# A33G53x register map
Vendor: ABOV Semiconductor Co., Ltd.; File version: 0.1
CPU: CM3 r1p0, little endian, no MPU, no FPU, 3 interrupt priority bits
Registers are 32-bit, read-write, reset 0x0 unless marked. A register's access mark holds for its fields unless they carry their own. Offsets are from the block's base; [hi:lo] are bit positions; {n}, {i} and the like mark numbered series.

## FMC — INTERNAL FLASH MEMORY
Base 0x40000100
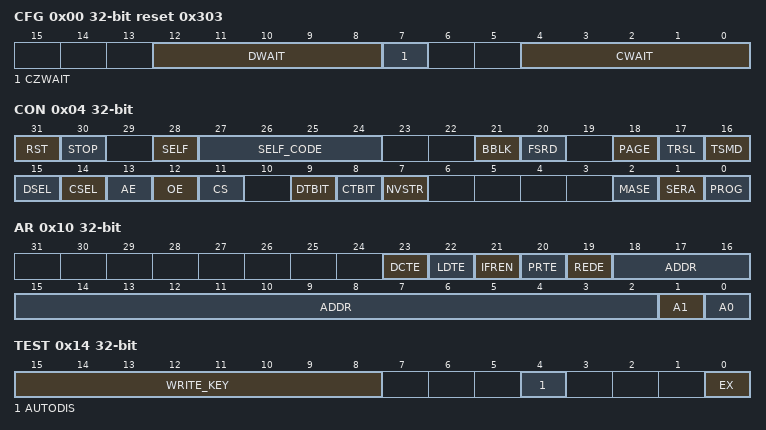
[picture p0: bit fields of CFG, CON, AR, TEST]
0x00 CFG reset 0x303 — Flash Memory Configuration Register
  [12:8] DWAIT — Wait value of data flash memory
  [7] CZWAIT — Zero wait value of code flash memory
  [4:0] CWAIT — Wait value of code flash memory
0x04 CON — Flash Memory Control Register
  [31] RST — Flash Reset Signal Control
  [30] STOP — Flash Status Control
  [28] SELF — Flash Self Program Control
  [27:24] SELF_CODE — Flash self program mode, can be written in conjunction with the PMCON[27:24] = 0110
  [21] BBLK — Boot Block Protection
  [20] FSRD — Fuse area activation(for flash internal test)
  [18] PAGE — Erase flash on a page(512 bytes) unit. Not supported in self-program mode
  [17] TRSL — Allow access to registers for flash testing(For flash internal test)
  [16] TSMD — Enter Test Mode(for flash internal test)
  [15] DSEL — Data Flash Select
  [14] CSEL — Code Flash Select
  [13] AE — Address Latch Enable
  [12] OE — Output Enable(Code flash program mode)
  [11] CS — Chip Select(Select Flash Rom)
  [9] DTBIT ro — Data Flash WRITE/ERASE Status Flag
  [8] CTBIT ro — Code Flash WRITE/ERASE Status Flag
  [7] NVSTR — Flash Memory WRITE/ERASE Start
  [2] MASE — Select Code or Data Flash Macro Erase
  [1] SERA — Erase flash in sectors(1KB) unit
  [0] PROG — Select Code or Data Flash for Write
0x08 ODR — Flash Memory Output Data Register
  [31:0] ODR — Output Data to the Flash Memories
0x0C IDR ro — Flash Memory Input Data Register
  [31:0] FMIDR — Input Data from the Flash Memories
0x10 AR — Flash Memory Address Register
  [23] DCTE — Always 0 (prohibited to write 1)
  [22] LDTE — Always 0 (prohibited to write 1)
  [21] IFREN — Always 0 (prohibited to write 1)
  [20] PRTE — Always 0 (prohibited to write 1)
  [19] REDE — Always 0 (prohibited to write 1)
  [18:2] ADDR — Flash Memory Address Value
  [1] A1 — Address A1 for Data Flash Memory
  [0] A0 — Address A0 for Data Flash Memory
0x14 TEST — Flash Memory Extended Mode Control Register
  [15:8] WRITE_KEY — To write values to the AUTODIS and EX fields, you must write the WRITE KEY. (WRITE KEY: 0x4A)
  [4] AUTODIS — NVSTR auto-clear
  [0] EX — Extended mode enable/disable
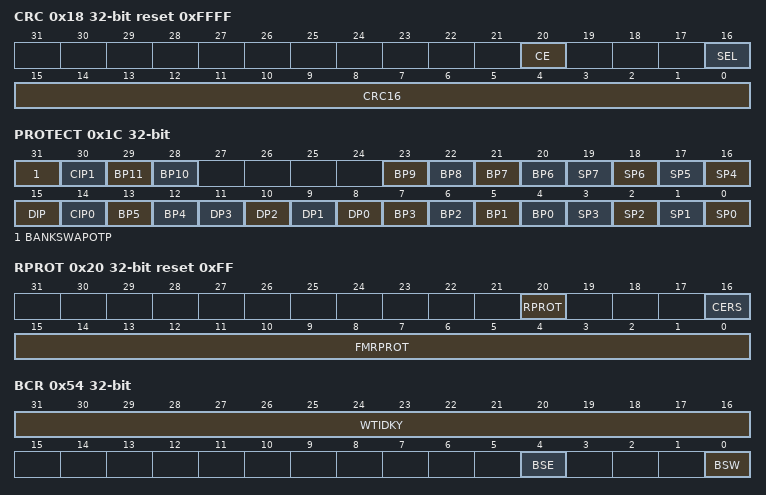
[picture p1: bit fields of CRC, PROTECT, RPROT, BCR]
0x18 CRC reset 0xFFFF — Flash Memory CRC Register
  [20] CE — CRC16 Enable/Disable
  [16] SEL — Selecting data to be input to CRC16
  [15:0] CRC16 — CRC16 Calculated value
0x1C PROTECT — Flash Memory Protection Register
  [31] BANKSWAPOTP — Protection bit from Bankswap
  [30] CIP1 — Always 0
  [29] BP11 — Protection bit from 0x000B_0000 to 0x000B_FFFF (768KB)
  [28] BP10 — Protection bit from 0x000A_0000 to 0x000A_FFFF (768KB)
  [23] BP9 — Protection bit from 0x0009_0000 to 0x0009_FFFF (768KB) Protection bit from 0x0007_0000 to 0x0007_FFFF (512KB)
  [22] BP8 — Protection bit from 0x0008_0000 to 0x0008_FFFF (768KB) Protection bit from 0x0006_0000 to 0x0006_FFFF (512KB)
  [21] BP7 — Protection bit from 0x0007_0000 to 0x0007_FFFF (768KB) Protection bit from 0x0005_0000 to 0x0005_FFFF (512KB)
  [20] BP6 — Protection bit from 0x0006_4000 to 0x0006_FFFF (768KB) Protection bit from 0x0004_4000 to 0x0004_FFFF (512KB)
  [n+12] SP{n} (n=4..7) — Protection bit from 0x0006_{1000n-4000:04} to 0x0006_{n-4}FFF (768KB) Protection bit from 0x0004_{1000n-4000:04} to 0x0004_{n-4}FFF (512KB)
  [15] DIP — Always 0
  [14] CIP0 — Always 0
  [13] BP5 — Protection bit from 0x0005_0000 to 0x0005_FFFF
  [12] BP4 — Protection bit from 0x0004_0000 to 0x0004_FFFF
  [n+8] DP{n} (n=0..3) — Protection bit of the Data Flash 8KB #{n}
  [7] BP3 — Protection bit from 0x0003_0000 to 0x0003_FFFF
  [6] BP2 — Protection bit from 0x0002_0000 to 0x0002_FFFF
  [5] BP1 — Protection bit from 0x0001_0000 to 0x0001_FFFF
  [4] BP0 — Protection bit from 0x0000_4000 to 0x0000_FFFF
  [n] SP{n} (n=0..3) — Protection bit from 0x0000_{1000n:04} to 0x0000_{n}FFF
0x20 RPROT reset 0xFF (reset mask 0x500000FF) — Flash Memory Read Protection Register
  [20] RPROT — Read Protection Status enable/disable
  [16] CERS — Chip Erase Status.This bit is set to 1 when the Chip Erase command is executed during the erase command
  [15:0] FMRPROT — Read Protection Setting
0x48 ECCTLSBER — Flash Memory ECC Test LSB Error Register
0x4C ECCTMSBER — Flash Memory ECC Test MSB Error Register
0x54 BCR — Flash Memory Bank Control Register
  [31:16] WTIDKY — Write identification key(0xAA91)
  [4] BSE — Memory Bank Selection Enable bit for swap operation.
  [0] BSW — Bank Swap operation (This bit must be set with WTIDKY and the BSE bit set to 1)
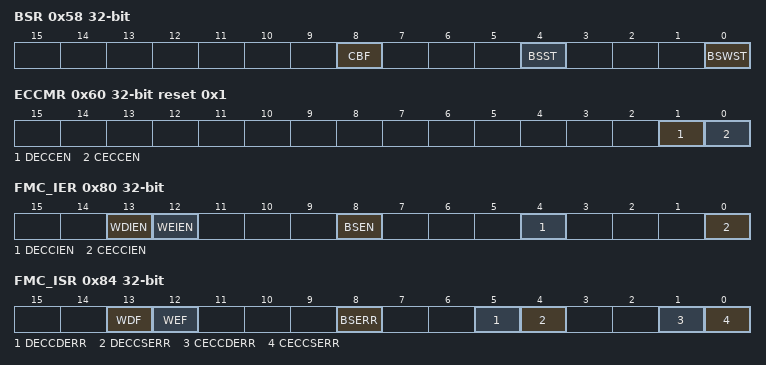
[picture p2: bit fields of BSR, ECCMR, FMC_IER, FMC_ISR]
0x58 BSR — Flash Memory Bank Status Register
  [8] CBF — Current boot bank flag bit
  [4] BSST — Bank selection status bit
  [0] BSWST — Bank swap status bit
0x60 ECCMR reset 0x1 — Flash Memory ECC Mode Register
  [1] DECCEN — Data Flash ECC Disable/Enable
  [0] CECCEN — Code Flash ECC Disable/Enable
0x64 CECCEAR — Code Flash Memroy ECC Error Address Register
0x68 CECCELSBDR — Code Flash Memory ECC Error LSB Data Register
0x6C CECCEMSBDR — Code Flash Memory ECC Error MSB Data Register
0x70 DECCEAR — Data Flash Memory ECC Error Address Register
0x74 DECCELSBDR — Data Flash Memory ECC Error LSB Data Register
0x78 DECCEMSBDR — Data Flash Memory ECC Error MSB Data Register
0x80 FMC_IER — Flash Memory Interrupt Enable Register
  [13] WDIEN — write done interrupt enable
  [12] WEIEN — write error interrupt enable
  [8] BSEN — Bank swap Error handling flag interrupt enable
  [4] DECCIEN — data flash ECC Error handling flag interrupt enable
  [0] CECCIEN — code flash ECC Error handling flag interrupt enable
0x84 FMC_ISR — Flash Memory Interrupt Status Register
  [13] WDF — success write in boot swap enable mode and self pgm mode
  [12] WEF — writing in boot swap enable mode and self pgm mode
  [8] BSERR — Error handling flag bit for bank selection If the bank selection malfunctions, BSERR bit is set to 1.
  [5] DECCDERR — Data flash ECC double Error status
  [4] DECCSERR — Data flash ECC single Error status
  [1] CECCDERR — Code flash ECC double Error status
  [0] CECCSERR — Code flash ECC single Error status
